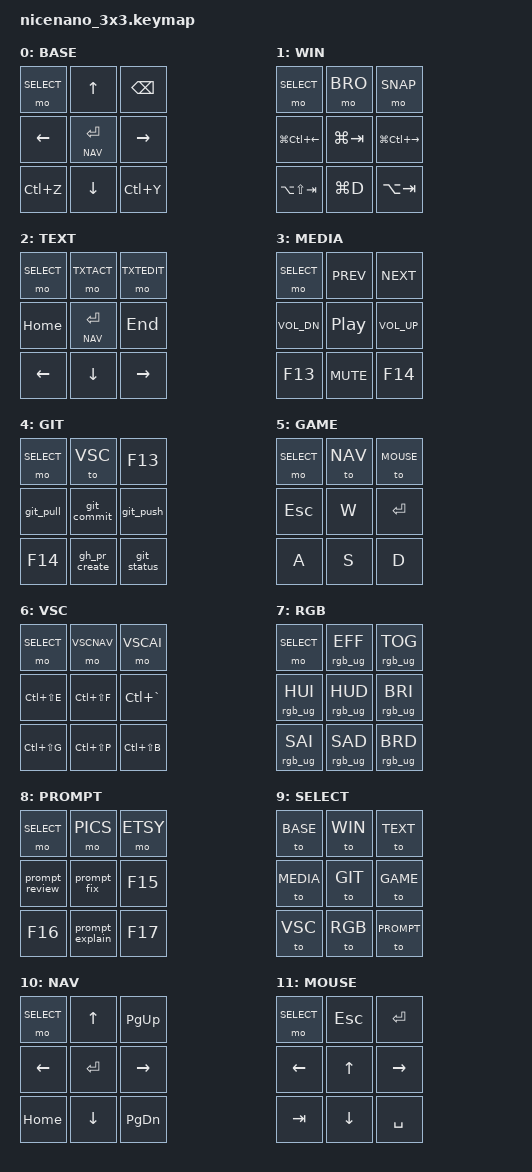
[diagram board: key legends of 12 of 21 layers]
#include <behaviors.dtsi>
#include <dt-bindings/zmk/keys.h>
#include <dt-bindings/zmk/bt.h>
#include <dt-bindings/zmk/rgb.h>

#define BASE     0
#define WIN      1
#define TEXT     2
#define MEDIA    3
#define GIT      4
#define GAME     5
#define VSC      6
#define RGB      7
#define PROMPT   8
#define SELECT   9
#define NAV      10
#define MOUSE    11
#define BTSYS    12
#define BRO      13
#define SNAP     14
#define TXTACT   15
#define TXTEDIT  16
#define VSCNAV   17
#define VSCAI    18
#define PICS     19
#define ETSY     20

/ {
    macros {
        git_pull: git_pull {
            compatible = "zmk,behavior-macro";
            label = "GIT_PULL";
            #binding-cells = <0>;
            wait-ms = <30>;
            tap-ms = <30>;
            bindings = <&kp G &kp I &kp T &kp SPACE &kp P &kp U &kp L &kp L &kp ENTER>;
        };

        git_status: git_status {
            compatible = "zmk,behavior-macro";
            label = "GIT_STATUS";
            #binding-cells = <0>;
            wait-ms = <30>;
            tap-ms = <30>;
            bindings = <&kp G &kp I &kp T &kp SPACE &kp S &kp T &kp A &kp T &kp U &kp S &kp ENTER>;
        };

        git_push: git_push {
            compatible = "zmk,behavior-macro";
            label = "GIT_PUSH";
            #binding-cells = <0>;
            wait-ms = <30>;
            tap-ms = <30>;
            bindings = <&kp G &kp I &kp T &kp SPACE &kp P &kp U &kp S &kp H &kp ENTER>;
        };

        git_commit: git_commit {
            compatible = "zmk,behavior-macro";
            label = "GIT_COMMIT";
            #binding-cells = <0>;
            wait-ms = <30>;
            tap-ms = <30>;
            bindings = <
                &kp G &kp I &kp T &kp SPACE &kp A &kp D &kp D &kp SPACE &kp DOT &kp ENTER
                &kp G &kp I &kp T &kp SPACE &kp C &kp O &kp M &kp M &kp I &kp T &kp SPACE &kp MINUS &kp M &kp SPACE
            >;
        };

        gh_pr_create: gh_pr_create {
            compatible = "zmk,behavior-macro";
            label = "GH_PR_CREATE";
            #binding-cells = <0>;
            wait-ms = <30>;
            tap-ms = <30>;
            bindings = <
                &kp G &kp H &kp SPACE &kp P &kp R &kp SPACE &kp C &kp R &kp E &kp A &kp T &kp E
                &kp SPACE &kp MINUS &kp MINUS &kp W &kp E &kp B &kp ENTER
            >;
        };

        prompt_review: prompt_review {
            compatible = "zmk,behavior-macro";
            label = "PROMPT_REVIEW";
            #binding-cells = <0>;
            wait-ms = <30>;
            tap-ms = <30>;
            bindings = <
                &kp R &kp E &kp V &kp I &kp E &kp W &kp SPACE
                &kp T &kp H &kp I &kp S &kp SPACE
                &kp C &kp O &kp D &kp E &kp SPACE
                &kp F &kp O &kp R &kp SPACE
                &kp B &kp U &kp G &kp S &kp PERIOD
            >;
        };

        prompt_fix: prompt_fix {
            compatible = "zmk,behavior-macro";
            label = "PROMPT_FIX";
            #binding-cells = <0>;
            wait-ms = <30>;
            tap-ms = <30>;
            bindings = <
                &kp S &kp U &kp G &kp G &kp E &kp S &kp T &kp SPACE
                &kp A &kp SPACE
                &kp M &kp I &kp N &kp I &kp M &kp A &kp L &kp SPACE
                &kp S &kp A &kp F &kp E &kp SPACE
                &kp F &kp I &kp X &kp PERIOD
            >;
        };

        prompt_explain: prompt_explain {
            compatible = "zmk,behavior-macro";
            label = "PROMPT_EXPLAIN";
            #binding-cells = <0>;
            wait-ms = <30>;
            tap-ms = <30>;
            bindings = <
                &kp E &kp X &kp P &kp L &kp A &kp I &kp N &kp SPACE
                &kp T &kp H &kp I &kp S &kp SPACE
                &kp C &kp O &kp D &kp E &kp SPACE
                &kp C &kp L &kp E &kp A &kp R &kp L &kp Y &kp PERIOD
            >;
        };

        prompt_etsy_tags: prompt_etsy_tags {
            compatible = "zmk,behavior-macro";
            label = "PROMPT_ETSY_TAGS";
            #binding-cells = <0>;
            wait-ms = <30>;
            tap-ms = <30>;
            bindings = <
                &kp G &kp E &kp N &kp E &kp R &kp A &kp T &kp E &kp SPACE
                &kp E &kp T &kp S &kp Y &kp SPACE
                &kp T &kp A &kp G &kp S &kp SPACE
                &kp I &kp N &kp SPACE
                &kp O &kp N &kp E &kp SPACE
                &kp R &kp O &kp W &kp PERIOD
            >;
        };
    };

    keymap {
        compatible = "zmk,keymap";

        base_layer {
            display-name = "BASE";
            bindings = <
                &mo SELECT  &kp UP         &kp BSPC
                &kp LEFT    &lt NAV ENTER  &kp RIGHT
                &kp LC(Z)   &kp DOWN       &kp LC(Y)
            >;
            sensor-bindings = <&inc_dec_kp C_VOL_UP C_VOL_DN>;
        };

        window_layer {
            display-name = "WIN";
            bindings = <
                &mo SELECT       &mo BRO       &mo SNAP
                &kp LG(LC(LEFT)) &kp LG(TAB)   &kp LG(LC(RIGHT))
                &kp LA(LS(TAB))  &kp LG(D)     &kp LA(TAB)
            >;
            sensor-bindings = <&inc_dec_kp LA(TAB) LA(LS(TAB))>;
        };

        text_layer {
            display-name = "TEXT";
            bindings = <
                &mo SELECT  &mo TXTACT      &mo TXTEDIT
                &kp HOME    &lt NAV ENTER   &kp END
                &kp LEFT    &kp DOWN        &kp RIGHT
            >;
            sensor-bindings = <&inc_dec_kp RIGHT LEFT>;
        };

        media_layer {
            display-name = "MEDIA";
            bindings = <
                &mo SELECT    &kp C_PREV        &kp C_NEXT
                &kp C_VOL_DN  &kp C_PLAY_PAUSE  &kp C_VOL_UP
                &kp F13       &kp C_MUTE        &kp F14
            >;
            sensor-bindings = <&inc_dec_kp C_VOL_UP C_VOL_DN>;
        };

        git_layer {
            display-name = "GIT";
            bindings = <
                &mo SELECT   &to VSC        &kp F13
                &git_pull    &git_commit    &git_push
                &kp F14      &gh_pr_create  &git_status
            >;
            sensor-bindings = <&inc_dec_kp RIGHT LEFT>;
        };

        game_layer {
            display-name = "GAME";
            bindings = <
                &mo SELECT  &to NAV  &to MOUSE
                &kp ESC     &kp W    &kp ENTER
                &kp A       &kp S    &kp D
            >;
            sensor-bindings = <&inc_dec_kp C_VOL_UP C_VOL_DN>;
        };

        vsc_layer {
            display-name = "VSC";
            bindings = <
                &mo SELECT       &mo VSCNAV      &mo VSCAI
                &kp LC(LS(E))    &kp LC(LS(F))   &kp LC(GRAVE)
                &kp LC(LS(G))    &kp LC(LS(P))   &kp LC(LS(B))
            >;
            sensor-bindings = <&inc_dec_kp PG_DN PG_UP>;
        };

        rgb_layer {
            display-name = "RGB";
            bindings = <
                &mo SELECT       &rgb_ug RGB_EFF  &rgb_ug RGB_TOG
                &rgb_ug RGB_HUI  &rgb_ug RGB_HUD  &rgb_ug RGB_BRI
                &rgb_ug RGB_SAI  &rgb_ug RGB_SAD  &rgb_ug RGB_BRD
            >;
            sensor-bindings = <&inc_dec_kp C_VOL_UP C_VOL_DN>;
        };

        prompt_layer {
            display-name = "PROMPT";
            bindings = <
                &mo SELECT      &mo PICS          &mo ETSY
                &prompt_review  &prompt_fix       &kp F15
                &kp F16         &prompt_explain   &kp F17
            >;
            sensor-bindings = <&inc_dec_kp PG_DN PG_UP>;
        };

        select_layer {
            display-name = "SELECT";
            bindings = <
                &to BASE   &to WIN   &to TEXT
                &to MEDIA  &to GIT   &to GAME
                &to VSC    &to RGB   &to PROMPT
            >;
            sensor-bindings = <&inc_dec_kp C_VOL_UP C_VOL_DN>;
        };

        nav_layer {
            display-name = "NAV";
            bindings = <
                &mo SELECT  &kp UP      &kp PG_UP
                &kp LEFT    &kp ENTER   &kp RIGHT
                &kp HOME    &kp DOWN    &kp PG_DN
            >;
            sensor-bindings = <&inc_dec_kp PG_DN PG_UP>;
        };

        mouse_placeholder_layer {
            display-name = "MOUSE";
            bindings = <
                &mo SELECT  &kp ESC    &kp ENTER
                &kp LEFT    &kp UP     &kp RIGHT
                &kp TAB     &kp DOWN   &kp SPACE
            >;
            sensor-bindings = <&inc_dec_kp C_VOL_UP C_VOL_DN>;
        };

        bt_sys_layer {
            display-name = "BT/SYS";
            bindings = <
                &bt BT_SEL 0  &bt BT_SEL 1  &bt BT_SEL 2
                &bt BT_SEL 3  &bt BT_SEL 4  &bt BT_CLR
                &bootloader   &sys_reset    &to BASE
            >;
            sensor-bindings = <&inc_dec_kp C_VOL_UP C_VOL_DN>;
        };

        window_browser_layer {
            display-name = "BRO";
            bindings = <
                &mo SELECT     &trans       &trans
                &kp C_PREV     &kp F5       &kp C_NEXT
                &kp LC(PG_UP)  &kp LC(T)    &kp LC(PG_DN)
            >;
            sensor-bindings = <&inc_dec_kp LC(PG_DN) LC(PG_UP)>;
        };

        window_snap_layer {
            display-name = "SNAP";
            bindings = <
                &mo SELECT    &trans       &trans
                &kp LG(UP)    &kp LG(UP)   &kp LG(DOWN)
                &kp LG(LEFT)  &kp LG(DOWN) &kp LG(RIGHT)
            >;
            sensor-bindings = <&inc_dec_kp LG(RIGHT) LG(LEFT)>;
        };

        text_actions_layer {
            display-name = "TXT-ACT";
            bindings = <
                &mo SELECT  &trans    &trans
                &kp LC(A)   &kp LC(C) &kp LC(V)
                &kp LC(X)   &kp LC(Z) &kp LC(Y)
            >;
            sensor-bindings = <&inc_dec_kp RIGHT LEFT>;
        };

        text_edit_layer {
            display-name = "TXT-EDIT";
            bindings = <
                &mo SELECT  &trans      &trans
                &kp ENTER   &kp BSPC    &kp DEL
                &kp TAB     &kp SPACE   &kp LS(LSHIFT)
            >;
            sensor-bindings = <&inc_dec_kp LS(RIGHT) LS(LEFT)>;
        };

        vsc_nav_layer {
            display-name = "VSC-NAV";
            bindings = <
                &mo SELECT     &trans        &trans
                &kp LC(P)      &kp LC(LS(O)) &kp LC(GRAVE)
                &kp LA(LEFT)   &kp LC(LS(P)) &kp LA(RIGHT)
            >;
            sensor-bindings = <&inc_dec_kp PG_DN PG_UP>;
        };

        vsc_ai_layer {
            display-name = "VSC-AI";
            bindings = <
                &mo SELECT      &trans          &trans
                &prompt_explain &prompt_review  &prompt_fix
                &kp F18         &kp F19         &kp F20
            >;
            sensor-bindings = <&inc_dec_kp PG_DN PG_UP>;
        };

        prompt_pics_layer {
            display-name = "PICS";
            bindings = <
                &mo SELECT  &trans  &trans
                &kp F21     &kp F22 &kp F23
                &kp F24     &kp F13 &kp F14
            >;
            sensor-bindings = <&inc_dec_kp PG_DN PG_UP>;
        };

        prompt_etsy_layer {
            display-name = "ETSY";
            bindings = <
                &mo SELECT        &trans  &trans
                &prompt_etsy_tags &kp F15 &kp F16
                &kp F17           &kp F18 &kp F19
            >;
            sensor-bindings = <&inc_dec_kp PG_DN PG_UP>;
        };
    };
};
